VERSION "CANTraceLab synthetic demonstration"

NS_ :

BS_:
BU_: DemoNode

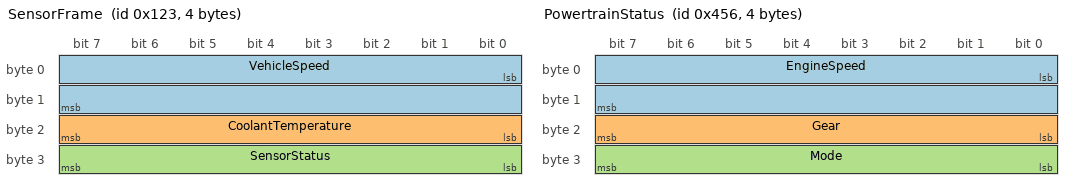
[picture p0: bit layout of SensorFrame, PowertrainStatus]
BO_ 291 SensorFrame: 4 DemoNode
 SG_ VehicleSpeed : 0|16@1+ (0.01,0) [0|655.35] "km/h" DemoNode
 SG_ CoolantTemperature : 16|8@1+ (1,0) [0|255] "degC" DemoNode
 SG_ SensorStatus : 24|8@1+ (1,0) [0|255] "" DemoNode

BO_ 1110 PowertrainStatus: 4 DemoNode
 SG_ EngineSpeed : 0|16@1+ (0.025,0) [0|1638.375] "rpm" DemoNode
 SG_ Gear : 16|8@1+ (1,0) [0|255] "" DemoNode
 SG_ Mode : 24|8@1+ (1,0) [0|255] "" DemoNode

VAL_ 1110 Mode 221 "Sport" 0 "Normal" ;
